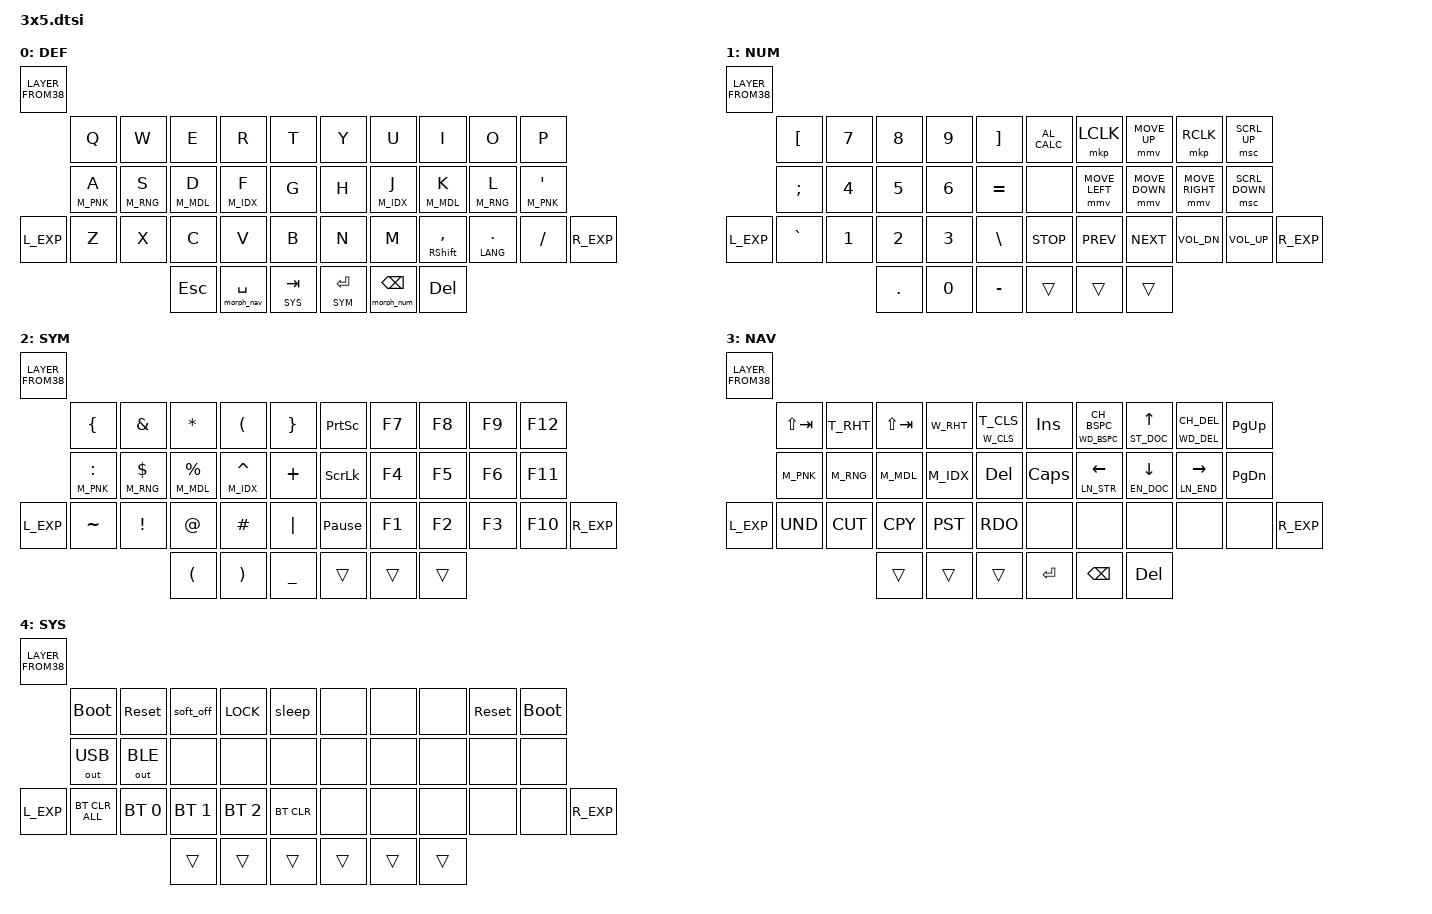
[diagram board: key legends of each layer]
#include <behaviors.dtsi>
#include <dt-bindings/zmk/keys.h>
#include <dt-bindings/zmk/bt.h>
#include <dt-bindings/zmk/outputs.h>
#include <behaviors/rgbled_widget.dtsi> // https://github.com/caksoylar/zmk-rgbled-widget
#include <behaviors/num_word.dtsi> // https://github.com/urob/zmk-auto-layer
#include "zmk-helpers/helper.h" //collection of helper macros. https://github.com/urob/zmk-helpers

// Layer aliases
#define DEF 0
#define NUM 1
#define SYM 2
#define NAV 3
#define SYS 4

#include "shortcut.dtsi"
#include "combos.dtsi"
#include "mouse.dtsi"
// #include "behaviors.dtsi"
#include "macros.dtsi"

#define QUICK_TAP_MS 175
#define REQUIRE_PRIOR_IDLE_MS 190

&mt {
    flavor = "hold-preferred";
    tapping-term-ms = <150>;
};

&sk {
  release-after-ms = <900>;
  quick-release;
};

&sl { // Allow sticky mods to chord across sticky layers.
  ignore-modifiers;
};

&lt {
  flavor = "balanced";
  tapping-term-ms = <200>;
  quick-tap-ms = <QUICK_TAP_MS>;
};

&caps_word {
    continue-list = <UNDERSCORE MINUS BSPC DEL N1 N2 N3 N4 N5 N6 N7 N8 N9 N0>;
};

/* auto-layers+zmk helpers */
// Tap: backspace | hold: layer | shift + hold: layer
#define NUM_BSPC &num_layer_ht 0 BSPC
ZMK_HOLD_TAP(num_layer_ht, bindings = <&morph_num>, <&kp>;
             flavor = "balanced"; tapping-term-ms = <200>;
             quick-tap-ms = <QUICK_TAP_MS>;)
ZMK_MOD_MORPH(morph_num, bindings = <&mo NUM>, <&to NUM>;
              mods = <(MOD_LSFT)>;)

// Tap: space | hold: layer | shift + hold: layer
#define NAV_SPC &nav_layer_ht 0 SPC
ZMK_HOLD_TAP(nav_layer_ht, bindings = <&morph_nav>, <&kp>;
             flavor = "balanced"; tapping-term-ms = <200>;
             quick-tap-ms = <QUICK_TAP_MS>;)
ZMK_MOD_MORPH(morph_nav, bindings = <&mo NAV>, <&to NAV>;
              mods = <(MOD_LSFT)>;)

/ {
    behaviors {
        aml: alpha_mods_l {
            compatible = "zmk,behavior-hold-tap";
            #binding-cells = <2>;
            tapping-term-ms = <220>;
            quick-tap-ms = <QUICK_TAP_MS>;
            require-prior-idle-ms = <165>;
            flavor = "balanced";
            bindings = <&kp>, <&kp>;
            hold-trigger-key-positions = <KEYS_R THUMBS>;
            hold-trigger-on-release;
            require-prior-idle-ms = <REQUIRE_PRIOR_IDLE_MS>;
        };
        asl: alpha_shift_l {
            compatible = "zmk,behavior-hold-tap";
            #binding-cells = <2>;
            tapping-term-ms = <200>;
            quick-tap-ms = <QUICK_TAP_MS>;
            flavor = "balanced";
            bindings = <&kp>, <&kp>;
            hold-trigger-key-positions = <KEYS_R THUMBS>;
            hold-trigger-on-release;
        };
        amr: alpha_mods_r {
            compatible = "zmk,behavior-hold-tap";
            #binding-cells = <2>;
            tapping-term-ms = <220>;
            quick-tap-ms = <QUICK_TAP_MS>;
            require-prior-idle-ms = <165>;
            flavor = "balanced";
            bindings = <&kp>, <&kp>;
            hold-trigger-key-positions = <KEYS_L THUMBS>;
            hold-trigger-on-release;
            require-prior-idle-ms = <REQUIRE_PRIOR_IDLE_MS>;
        };
        asr: alpha_shift_r {
            compatible = "zmk,behavior-hold-tap";
            #binding-cells = <2>;
            tapping-term-ms = <200>;
            quick-tap-ms = <QUICK_TAP_MS>;
            flavor = "balanced";
            bindings = <&kp>, <&kp>;
            hold-trigger-key-positions = <KEYS_L THUMBS>;     //같은 손에서 f를 누르고 tapping-term 시간 내에 a가 눌리면 mod+a가 아니라 fa로 출력 tap으로 인식 
            hold-trigger-on-release;                          //지정한 포지션 외에 tapping-term 시간내에 다른 키가 눌려도 먼저 눌린 키를 릴리즈로 인식 flavor문제 해결때
        };
        ht: hold_tap {
            compatible = "zmk,behavior-hold-tap";
            #binding-cells = <2>;
            tapping-term-ms = <200>;
            quick-tap-ms = <QUICK_TAP_MS>;
            flavor = "tap-preferred";
            bindings = <&kp>, <&kp>;
            hold-trigger-key-positions = <THUMBS>;            //지정한 포지션외에는 tapping-term 시간 내라도 tap으로 인식 
        };
        //test
        morph_NM: morph_NM {
            compatible = "zmk,behavior-mod-morph";
            #binding-cells = <0>;
            bindings = <&mo NUM>, <&to NUM>;
            mods = <(MOD_LSFT)>;
        };
        nm_ly_ht: nm_ly_ht {
            compatible = "zmk,behavior-hold-tap";
            #binding-cells = <2>;
            tapping-term-ms = <200>;
            quick-tap-ms = <QUICK_TAP_MS>;
            flavor = "balanced";
            bindings = <&morph_NM>, <&kp>;
        };
        // Swapper for smart alt+tab
        sw_a: swapper_alttab {
            compatible = "zmk,behavior-smart-toggle";
            #binding-cells = <0>;
            bindings = <&kp LALT>, <&kp TAB>;
            ignored-key-positions = <THUMBS LT4 LT2 RM1 RM2 RM3 RT2>;
        };
        sw_c: swapper_ctrltab {
            compatible = "zmk,behavior-smart-toggle";
            #binding-cells = <0>;
            bindings = <&kp LCTRL>, <&kp TAB>;
            ignored-key-positions = <THUMBS LT4 LT2 RM1 RM2 RM3 RT2>;
        };
        sw_g: swapper_guitab {
            compatible = "zmk,behavior-smart-toggle";
            #binding-cells = <0>;
            bindings = <&kp LGUI>, <&kp TAB>;
            ignored-key-positions = <THUMBS LT4 LT2 RM1 RM2 RM3 RT2>;
        };
    };
};

/ {
    keymap {
        compatible = "zmk,keymap";

        default_layer {
            display-name = "DEF";
            bindings = <LAYER_FROM38( \
//           ╭──────────────┬──────────────┬──────────────┬──────────────┬──────────────╮   ╭──────────────┬──────────────┬──────────────┬──────────────┬──────────────╮
              &kp Q,         &kp W,         &kp E,         &kp R,         &kp T,             &kp Y,         &kp U,         &kp I,         &kp O,         &kp P, \
              &aml M_PNK A,  &aml M_RNG S,  &asl M_MDL D,  &aml M_IDX F,  &kp G,             &kp H,         &amr M_IDX J,  &asr M_MDL K,  &amr M_RNG L,  &amr M_PNK SQT, \
&kp L_EXP,    &kp Z,         &kp X,         &kp C,         &kp V,         &kp B,             &kp N,         &kp M,       &mt RSHFT COMMA, &mt LANG DOT,  &kp SLASH, &kp R_EXP, \
                                            &kp ESC,       NAV_SPC,       &lt SYS TAB,       &lt SYM RET,   NUM_BSPC,      &kp DEL \
//                                         ╰─────────────┴──────────────┴──────────────╯    ╰──────────────┴──────────────┴──────────────╯
            )>;
        };

        number_layer {
            display-name = "NUM";
            bindings = <LAYER_FROM38( \
//           ╭──────────────┬──────────────┬──────────────┬──────────────┬──────────────╮   ╭──────────────┬──────────────┬──────────────┬──────────────┬──────────────╮
              &kp LBKT,      &kp N7,        &kp N8,        &kp N9,        &kp RBKT,          &kp C_AL_CALC, &mkp LCLK,     &mmv MOVE_UP,  &mkp RCLK,     &msc SCRL_UP, \
              &kp SEMI,      &kp N4,        &kp N5,        &kp N6,        &kp EQUAL,         &none,         &mmv MOVE_LEFT, &mmv MOVE_DOWN, &mmv MOVE_RIGHT, &msc SCRL_DOWN, \
&kp L_EXP,    &kp GRAVE,     &kp N1,        &kp N2,        &kp N3,        &kp BSLH,          &kp C_STOP,    &kp C_PREV,    &kp C_NEXT,    &kp C_VOL_DN,  &kp C_VOL_UP,  &kp R_EXP, \
                                            &kp DOT,       &kp N0,        &kp MINUS,         &trans,        &trans,        &trans \
//                                         ╰──────────────┴──────────────┴──────────────╯   ╰──────────────┴──────────────┴──────────────╯
            )>;
        };

        symbol_layer {
            display-name = "SYM";
            bindings = <LAYER_FROM38( \
//           ╭──────────────┬──────────────┬──────────────┬──────────────┬──────────────╮   ╭──────────────┬──────────────┬──────────────┬──────────────┬──────────────╮
              &kp LBRC,      &kp AMPS,      &kp ASTRK,     &kp LPAR,      &kp RBRC,          &kp PSCRN,     &kp F7,        &kp F8,        &kp F9,        &kp F12, \
              &mt M_PNK COLON, &mt M_RNG DLLR, &mt M_MDL PRCNT, &mt M_IDX CARET, &kp PLUS,   &kp SLCK,      &kp F4,        &kp F5,        &kp F6,        &kp F11, \
&kp L_EXP,    &kp TILDE,     &kp EXCL,      &kp AT,        &kp HASH,      &kp PIPE,          &kp PAUSE_BREAK, &kp F1,      &kp F2,        &kp F3,        &kp F10,       &kp R_EXP, \
                                            &kp LPAR,      &kp RPAR,      &kp UNDER,         &trans,        &trans,        &trans \
//                                         ╰──────────────┴──────────────┴──────────────╯   ╰──────────────┴──────────────┴──────────────╯
            )>;
        };

        navigation_layer {
            display-name = "NAV";
            bindings = <LAYER_FROM38( \
//           ╭──────────────┬──────────────┬──────────────┬──────────────┬──────────────╮   ╭──────────────┬──────────────┬──────────────┬──────────────┬──────────────╮
              &kp LS(TAB),   &T_RHT,        &kp LS(TAB),   &W_RHT,        &ht W_CLS T_CLS,   &kp INS,  &ht WD_BSPC CH_BSPC, &ht ST_DOC UP, &ht WD_DEL CH_DEL, &kp PG_UP, \
              &kp M_PNK,     &kp M_RNG,     &kp M_MDL,     &kp M_IDX,     &kp DEL,           &kp CAPS, &ht LN_STR LEFT,    &ht EN_DOC DOWN, &ht LN_END RIGHT, &kp PG_DN, \
&kp L_EXP,    &kp C_UND,     &kp C_CUT,     &kp C_CPY,     &kp C_PST,     &kp C_RDO,         &none,         &none,         &none,         &none,         &none,        &kp R_EXP, \
                                            &trans,        &trans,        &trans,            &kp RET,       &kp BSPC,      &kp DEL \
//                                         ╰──────────────┴──────────────┴──────────────╯   ╰──────────────┴──────────────┴──────────────╯
            )>;
        };

        system_layer {
            display-name = "SYS";
            bindings = <LAYER_FROM38( \
//           ╭──────────────┬──────────────┬──────────────┬──────────────┬──────────────╮   ╭──────────────┬──────────────┬──────────────┬──────────────┬──────────────╮
              &bootloader,   &sys_reset,    &soft_off,     &kp LOCK,      &sleep,            &none,         &none,         &none,         &sys_reset,    &bootloader, \
              &out OUT_USB,  &out OUT_BLE,  &none,         &none,         &none,             &none,         &none,         &none,         &none,         &none, \
&kp L_EXP,    &bt BT_CLR_ALL, &bt BT_SEL 0, &bt BT_SEL 1,  &bt BT_SEL 2,  &bt BT_CLR,        &none,         &none,         &none,         &none,         &none,        &kp R_EXP, \
                                            &trans,        &trans,        &trans,            &trans,        &trans,        &trans \
//                                         ╰──────────────┴──────────────┴──────────────╯   ╰──────────────┴──────────────┴──────────────╯
            )>;
        };
    };
};
